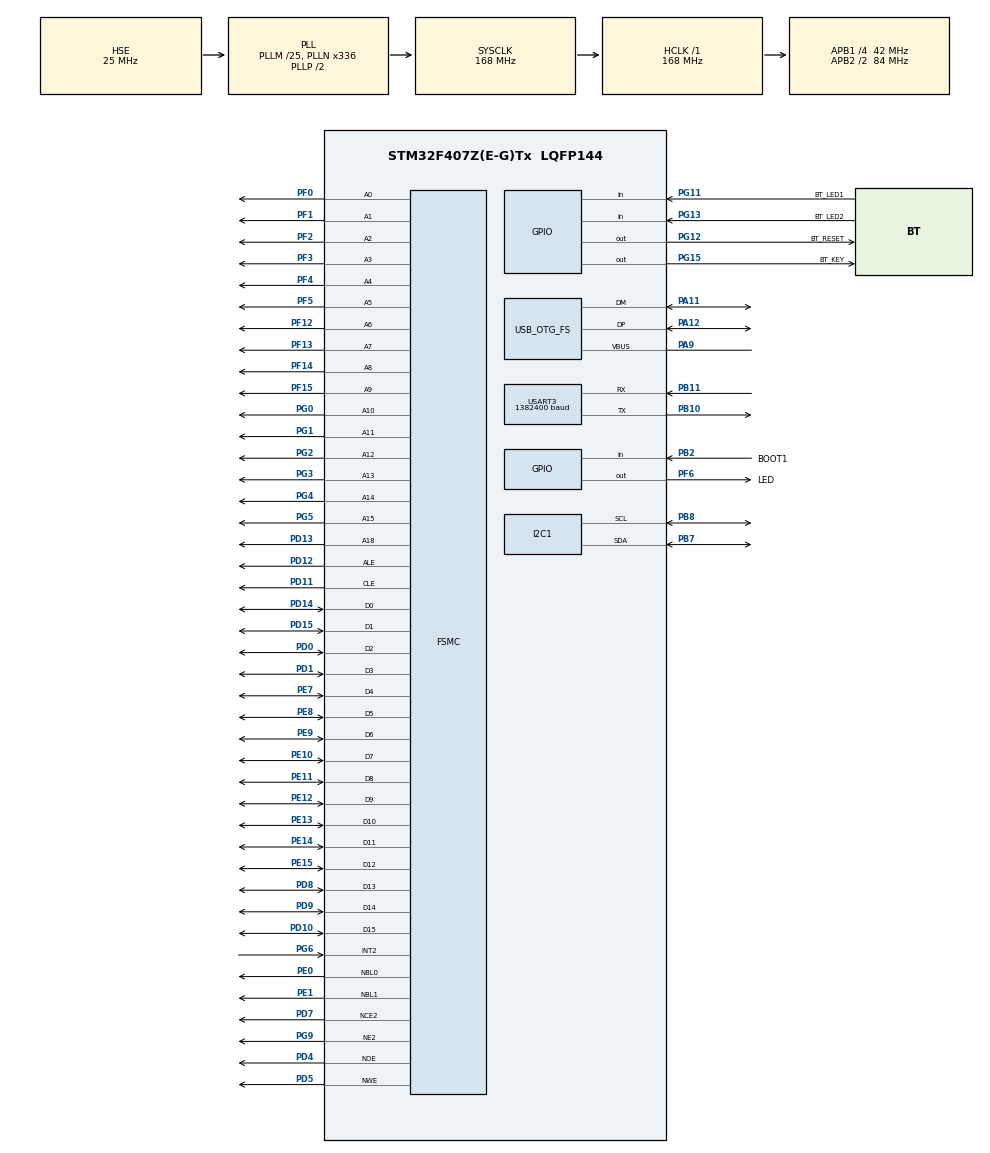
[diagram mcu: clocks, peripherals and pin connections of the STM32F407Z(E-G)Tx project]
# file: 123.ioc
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Dma.Request0=USART3_RX
Dma.Request1=USART3_TX
Dma.USART3_RX.0.Direction=DMA_PERIPH_TO_MEMORY
Dma.USART3_RX.0.FIFOMode=DMA_FIFOMODE_DISABLE
Dma.USART3_RX.0.Instance=DMA1_Stream1
Dma.USART3_RX.0.MemDataAlignment=DMA_MDATAALIGN_BYTE
Dma.USART3_RX.0.MemInc=DMA_MINC_ENABLE
Dma.USART3_RX.0.Mode=DMA_NORMAL
Dma.USART3_RX.0.PeriphDataAlignment=DMA_PDATAALIGN_BYTE
Dma.USART3_RX.0.PeriphInc=DMA_PINC_DISABLE
Dma.USART3_RX.0.Priority=DMA_PRIORITY_HIGH
Dma.USART3_TX.1.Direction=DMA_MEMORY_TO_PERIPH
Dma.USART3_TX.1.FIFOMode=DMA_FIFOMODE_DISABLE
Dma.USART3_TX.1.Instance=DMA1_Stream3
Dma.USART3_TX.1.MemDataAlignment=DMA_MDATAALIGN_BYTE
Dma.USART3_TX.1.MemInc=DMA_MINC_ENABLE
Dma.USART3_TX.1.Mode=DMA_NORMAL
Dma.USART3_TX.1.PeriphDataAlignment=DMA_PDATAALIGN_BYTE
Dma.USART3_TX.1.PeriphInc=DMA_PINC_DISABLE
Dma.USART3_TX.1.Priority=DMA_PRIORITY_LOW
FREERTOS.BinarySemaphores01=goToSendUSB,Dynamic,NULL
FREERTOS.HEAP_NUMBER=1
FREERTOS.INCLUDE_uxTaskPriorityGet=0
FREERTOS.INCLUDE_vTaskDelayUntil=0
FREERTOS.INCLUDE_vTaskDelete=0
FREERTOS.INCLUDE_vTaskPrioritySet=0
FREERTOS.Queues01=usbTransmitQueue,8,uint64_t,NULL,Dynamic,NULL,NULL
FREERTOS.Tasks01=defaultTask,-1,90,StartDefaultTask,As weak,NULL,Dynamic,NULL,NULL;usbTrans,-1,90,usbTransmit,As weak,NULL,Dynamic,NULL,NULL;myTask03,-1,90,taskIIC,As weak,NULL,Dynamic,NULL,NULL
FREERTOS.Timers01=statChange,statChangeTimer,osTimerPeriodic,As weak,NULL,Dynamic,NULL
FREERTOS.configMAX_TASK_NAME_LEN=12
FREERTOS.configMINIMAL_STACK_SIZE=90
FREERTOS.configTIMER_QUEUE_LENGTH=1
FREERTOS.configTIMER_TASK_PRIORITY=6
FREERTOS.configTIMER_TASK_STACK_DEPTH=90
FREERTOS.configTOTAL_HEAP_SIZE=3072
FREERTOS.configUSE_COUNTING_SEMAPHORES=0
FREERTOS.configUSE_TIMERS=1
Mcu.Family=STM32F4
Mcu.Name=STM32F407Z(E-G)Tx
Mcu.Package=LQFP144
NVIC.DMA1_Stream1_IRQn=true\:5\:0\:false\:false\:true\:true\:false
NVIC.DMA1_Stream3_IRQn=true\:5\:0\:true\:false\:true\:false\:false
NVIC.OTG_FS_IRQn=true\:5\:0\:true\:false\:true\:true\:true
NVIC.PriorityGroup=NVIC_PRIORITYGROUP_4
NVIC.TIM4_IRQn=true\:0\:0\:false\:false\:true\:false\:false
NVIC.TimeBase=TIM4_IRQn
NVIC.TimeBaseIP=TIM4
NVIC.USART3_IRQn=true\:5\:0\:true\:false\:true\:true\:true
PA11.Mode=Device_Only
PA11.Signal=USB_OTG_FS_DM
PA12.Mode=Device_Only
PA12.Signal=USB_OTG_FS_DP
PA13.Signal=SYS_JTMS-SWDIO
PA14.Signal=SYS_JTCK-SWCLK
PA9.Mode=Activate_VBUS
PA9.Signal=USB_OTG_FS_VBUS
PB10.Mode=Asynchronous
PB10.Signal=USART3_TX
PB11.Mode=Asynchronous
PB11.Signal=USART3_RX
PB2.GPIO_Label=BOOT1
PB2.Signal=GPIO_Input
PB3.Signal=SYS_JTDO-SWO
PB7.Mode=I2C
PB7.Signal=I2C1_SDA
PB8.Mode=I2C
PB8.Signal=I2C1_SCL
PC14-OSC32_IN.Mode=LSE-External-Oscillator
PC14-OSC32_IN.Signal=RCC_OSC32_IN
PC15-OSC32_OUT.Mode=LSE-External-Oscillator
PC15-OSC32_OUT.Signal=RCC_OSC32_OUT
PD0.Signal=FSMC_D2_DA2
PD1.Signal=FSMC_D3_DA3
PD10.Signal=FSMC_D15_DA15
PD11.Signal=FSMC_A16_CLE
PD12.Signal=FSMC_A17_ALE
PD13.Signal=FSMC_A18
PD14.Signal=FSMC_D0_DA0
PD15.Signal=FSMC_D1_DA1
PD4.Signal=FSMC_NOE
PD5.Signal=FSMC_NWE
PD7.Mode=NandChipSelect2_1
PD7.Signal=FSMC_NCE2
PD8.Signal=FSMC_D13_DA13
PD9.Signal=FSMC_D14_DA14
PE0.Signal=FSMC_NBL0
PE1.Signal=FSMC_NBL1
PE10.Signal=FSMC_D7_DA7
PE11.Signal=FSMC_D8_DA8
PE12.Signal=FSMC_D9_DA9
PE13.Signal=FSMC_D10_DA10
PE14.Signal=FSMC_D11_DA11
PE15.Signal=FSMC_D12_DA12
PE7.Signal=FSMC_D4_DA4
PE8.Signal=FSMC_D5_DA5
PE9.Signal=FSMC_D6_DA6
PF0.Signal=FSMC_A0
PF1.Signal=FSMC_A1
PF12.Signal=FSMC_A6
PF13.Signal=FSMC_A7
PF14.Signal=FSMC_A8
PF15.Signal=FSMC_A9
PF2.Signal=FSMC_A2
PF3.Signal=FSMC_A3
PF4.Signal=FSMC_A4
PF5.Signal=FSMC_A5
PF6.GPIO_Label=LED
PF6.Signal=GPIO_Output
PG0.Signal=FSMC_A10
PG1.Signal=FSMC_A11
PG11.GPIO_Label=BT_LED1
PG11.Signal=GPIO_Input
PG12.GPIO_Label=BT_RESET
PG12.GPIO_ModeDefaultOutputPP=GPIO_MODE_OUTPUT_OD
PG12.GPIO_PuPd=GPIO_NOPULL
PG12.PinState=GPIO_PIN_SET
PG12.Signal=GPIO_Output
PG13.GPIO_Label=BT_LED2
PG13.Signal=GPIO_Input
PG15.GPIO_Label=BT_KEY
PG15.GPIO_ModeDefaultOutputPP=GPIO_MODE_OUTPUT_PP
PG15.PinState=GPIO_PIN_RESET
PG15.Signal=GPIO_Output
PG2.Signal=FSMC_A12
PG3.Signal=FSMC_A13
PG4.Signal=FSMC_A14
PG5.Signal=FSMC_A15
PG6.Signal=FSMC_INT2
PG9.Mode=NorPsramChipSelect2_1
PG9.Signal=FSMC_NE2
PH0-OSC_IN.Mode=HSE-External-Oscillator
PH0-OSC_IN.Signal=RCC_OSC_IN
PH1-OSC_OUT.Mode=HSE-External-Oscillator
PH1-OSC_OUT.Signal=RCC_OSC_OUT
ProjectManager.HeapSize=0x600
ProjectManager.StackSize=0x800
ProjectManager.TargetToolchain=EWARM
RCC.48MHZClocksFreq_Value=48000000
RCC.AHBFreq_Value=168000000
RCC.APB1CLKDivider=RCC_HCLK_DIV4
RCC.APB1Freq_Value=42000000
RCC.APB1TimFreq_Value=84000000
RCC.APB2CLKDivider=RCC_HCLK_DIV2
RCC.APB2Freq_Value=84000000
RCC.APB2TimFreq_Value=168000000
RCC.CortexFreq_Value=168000000
RCC.EnbaleCSS=true
RCC.HCLKFreq_Value=168000000
RCC.HSE_VALUE=25000000
RCC.HSI_VALUE=16000000
RCC.PLLM=25
RCC.PLLN=336
RCC.PLLQ=7
RCC.RCC_RTC_Clock_SourceVirtual=RCC_RTCCLKSOURCE_LSE
RCC.SYSCLKFreq_VALUE=168000000
RCC.SYSCLKSource=RCC_SYSCLKSOURCE_PLLCLK
RCC.VCOOutputFreq_Value=336000000
SH.FSMC_A0.0=FSMC_A0,19b-a1
SH.FSMC_A1.0=FSMC_A1,19b-a1
SH.FSMC_A10.0=FSMC_A10,19b-a1
SH.FSMC_A11.0=FSMC_A11,19b-a1
SH.FSMC_A12.0=FSMC_A12,19b-a1
SH.FSMC_A13.0=FSMC_A13,19b-a1
SH.FSMC_A14.0=FSMC_A14,19b-a1
SH.FSMC_A15.0=FSMC_A15,19b-a1
SH.FSMC_A16_CLE.0=FSMC_CLE,8b-dmux1
SH.FSMC_A16_CLE.1=FSMC_A16,19b-a1
SH.FSMC_A17_ALE.0=FSMC_ALE,8b-dmux1
SH.FSMC_A17_ALE.1=FSMC_A17,19b-a1
SH.FSMC_A18.0=FSMC_A18,19b-a1
SH.FSMC_A2.0=FSMC_A2,19b-a1
SH.FSMC_A3.0=FSMC_A3,19b-a1
SH.FSMC_A4.0=FSMC_A4,19b-a1
SH.FSMC_A5.0=FSMC_A5,19b-a1
SH.FSMC_A6.0=FSMC_A6,19b-a1
SH.FSMC_A7.0=FSMC_A7,19b-a1
SH.FSMC_A8.0=FSMC_A8,19b-a1
SH.FSMC_A9.0=FSMC_A9,19b-a1
SH.FSMC_D0_DA0.0=FSMC_D0,8b-dmux1
SH.FSMC_D0_DA0.1=FSMC_D0,16b-d1
SH.FSMC_D10_DA10.0=FSMC_D10,16b-d1
SH.FSMC_D11_DA11.0=FSMC_D11,16b-d1
SH.FSMC_D12_DA12.0=FSMC_D12,16b-d1
SH.FSMC_D13_DA13.0=FSMC_D13,16b-d1
SH.FSMC_D14_DA14.0=FSMC_D14,16b-d1
SH.FSMC_D15_DA15.0=FSMC_D15,16b-d1
SH.FSMC_D1_DA1.0=FSMC_D1,8b-dmux1
SH.FSMC_D1_DA1.1=FSMC_D1,16b-d1
SH.FSMC_D2_DA2.0=FSMC_D2,8b-dmux1
SH.FSMC_D2_DA2.1=FSMC_D2,16b-d1
SH.FSMC_D3_DA3.0=FSMC_D3,8b-dmux1
SH.FSMC_D3_DA3.1=FSMC_D3,16b-d1
SH.FSMC_D4_DA4.0=FSMC_D4,8b-dmux1
SH.FSMC_D4_DA4.1=FSMC_D4,16b-d1
SH.FSMC_D5_DA5.0=FSMC_D5,8b-dmux1
SH.FSMC_D5_DA5.1=FSMC_D5,16b-d1
SH.FSMC_D6_DA6.0=FSMC_D6,8b-dmux1
SH.FSMC_D6_DA6.1=FSMC_D6,16b-d1
SH.FSMC_D7_DA7.0=FSMC_D7,8b-dmux1
SH.FSMC_D7_DA7.1=FSMC_D7,16b-d1
SH.FSMC_D8_DA8.0=FSMC_D8,16b-d1
SH.FSMC_D9_DA9.0=FSMC_D9,16b-d1
SH.FSMC_INT2.0=FSMC_INT2,Interrupt21
SH.FSMC_NBL0.0=FSMC_NBL0,2ByteEnable1
SH.FSMC_NBL1.0=FSMC_NBL1,2ByteEnable1
SH.FSMC_NOE.0=FSMC_NOE,8b-dmux1
SH.FSMC_NOE.1=FSMC_NOE,Sram1
SH.FSMC_NWE.0=FSMC_NWE,8b-dmux1
SH.FSMC_NWE.1=FSMC_NWE,Sram1
USART3.BaudRate=1382400
USART3.Mode=MODE_TX_RX
USART3.OverSampling=UART_OVERSAMPLING_16
USART3.VirtualMode=VM_ASYNC
USB_OTG_FS.VirtualMode=Device_Only
VP_FREERTOS_VS_ENABLE.Mode=Enabled
VP_SYS_VS_tim4.Mode=TIM4
board=123

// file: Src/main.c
/**
  ******************************************************************************
  * File Name          : main.c
  * Description        : Main program body
  ******************************************************************************
  * This notice applies to any and all portions of this file
  * that are not between comment pairs USER CODE BEGIN and
  * USER CODE END. Other portions of this file, whether
  * inserted by the user or by software development tools
  * are owned by their respective copyright owners.
  *
  * Copyright (c) 2017 STMicroelectronics International N.V.
  * All rights reserved.
  *
  * Redistribution and use in source and binary forms, with or without
  * modification, are permitted, provided that the following conditions are met:
  *
  * 1. Redistribution of source code must retain the above copyright notice,
  *    this list of conditions and the following disclaimer.
  * 2. Redistributions in binary form must reproduce the above copyright notice,
  *    this list of conditions and the following disclaimer in the documentation
  *    and/or other materials provided with the distribution.
  * 3. Neither the name of STMicroelectronics nor the names of other
  *    contributors to this software may be used to endorse or promote products
  *    derived from this software without specific written permission.
  * 4. This software, including modifications and/or derivative works of this
  *    software, must execute solely and exclusively on microcontroller or
  *    microprocessor devices manufactured by or for STMicroelectronics.
  * 5. Redistribution and use of this software other than as permitted under
  *    this license is void and will automatically terminate your rights under
  *    this license.
  *
  * THIS SOFTWARE IS PROVIDED BY STMICROELECTRONICS AND CONTRIBUTORS "AS IS"
  * AND ANY EXPRESS, IMPLIED OR STATUTORY WARRANTIES, INCLUDING, BUT NOT
  * LIMITED TO, THE IMPLIED WARRANTIES OF MERCHANTABILITY, FITNESS FOR A
  * PARTICULAR PURPOSE AND NON-INFRINGEMENT OF THIRD PARTY INTELLECTUAL PROPERTY
  * RIGHTS ARE DISCLAIMED TO THE FULLEST EXTENT PERMITTED BY LAW. IN NO EVENT
  * SHALL STMICROELECTRONICS OR CONTRIBUTORS BE LIABLE FOR ANY DIRECT, INDIRECT,
  * INCIDENTAL, SPECIAL, EXEMPLARY, OR CONSEQUENTIAL DAMAGES (INCLUDING, BUT NOT
  * LIMITED TO, PROCUREMENT OF SUBSTITUTE GOODS OR SERVICES; LOSS OF USE, DATA,
  * OR PROFITS; OR BUSINESS INTERRUPTION) HOWEVER CAUSED AND ON ANY THEORY OF
  * LIABILITY, WHETHER IN CONTRACT, STRICT LIABILITY, OR TORT (INCLUDING
  * NEGLIGENCE OR OTHERWISE) ARISING IN ANY WAY OUT OF THE USE OF THIS SOFTWARE,
  * EVEN IF ADVISED OF THE POSSIBILITY OF SUCH DAMAGE.
  *
  ******************************************************************************
  */

#include "main.h"
#include "stm32f4xx_hal.h"
#include "cmsis_os.h"
#include "dma.h"
#include "i2c.h"
#include "usart.h"
#include "usb_otg.h"
#include "gpio.h"
#include "fsmc.h"

/* USER CODE BEGIN PV */
/* Private variables ---------------------------------------------------------*/

/* USER CODE END PV */

void SystemClock_Config(void);
void MX_FREERTOS_Init(void);

/* USER CODE BEGIN PFP */
/* Private function prototypes -----------------------------------------------*/

/* USER CODE END PFP */

int main(void)
{

  /* MCU Configuration----------------------------------------------------------*/

  /* Reset of all peripherals, Initializes the Flash interface and the Systick. */
  HAL_Init();

  /* Configure the system clock */
  SystemClock_Config();

  /* USER CODE BEGIN SysInit */
#ifdef _KJKJKJKJ
  /* USER CODE END SysInit */

  /* Initialize all configured peripherals */
  MX_GPIO_Init();
  MX_DMA_Init();
  MX_FSMC_Init();
  MX_USART3_UART_Init();
  MX_USB_OTG_FS_PCD_Init();
  MX_I2C1_Init();

  /* USER CODE BEGIN 2 */
#endif

  MX_GPIO_Init();
  MX_DMA_Init();
  MX_FSMC_Init();
  MX_USART3_UART_Init();
  MX_USB_OTG_FS_PCD_Init();
  MX_I2C1_Init();

  /* USER CODE END 2 */

  /* Call init function for freertos objects (in freertos.c) */
  MX_FREERTOS_Init();

  /* Start scheduler */
  osKernelStart();

  /* We should never get here as control is now taken by the scheduler */

  /* Infinite loop */
  while (1)
  {

  }

}

/** System Clock Configuration
*/
void SystemClock_Config(void)
{

  RCC_OscInitTypeDef RCC_OscInitStruct;
  RCC_ClkInitTypeDef RCC_ClkInitStruct;

    /**Configure the main internal regulator output voltage
    */
  __HAL_RCC_PWR_CLK_ENABLE();

  __HAL_PWR_VOLTAGESCALING_CONFIG(PWR_REGULATOR_VOLTAGE_SCALE1);

    /**Initializes the CPU, AHB and APB busses clocks
    */
  RCC_OscInitStruct.OscillatorType = RCC_OSCILLATORTYPE_HSE;
  RCC_OscInitStruct.HSEState = RCC_HSE_ON;
  RCC_OscInitStruct.PLL.PLLState = RCC_PLL_ON;
  RCC_OscInitStruct.PLL.PLLSource = RCC_PLLSOURCE_HSE;
  RCC_OscInitStruct.PLL.PLLM = 25;
  RCC_OscInitStruct.PLL.PLLN = 336;
  RCC_OscInitStruct.PLL.PLLP = RCC_PLLP_DIV2;
  RCC_OscInitStruct.PLL.PLLQ = 7;
  if (HAL_RCC_OscConfig(&RCC_OscInitStruct) != HAL_OK)
  {
    _Error_Handler(__FILE__, __LINE__);
  }

    /**Initializes the CPU, AHB and APB busses clocks
    */
  RCC_ClkInitStruct.ClockType = RCC_CLOCKTYPE_HCLK|RCC_CLOCKTYPE_SYSCLK
                              |RCC_CLOCKTYPE_PCLK1|RCC_CLOCKTYPE_PCLK2;
  RCC_ClkInitStruct.SYSCLKSource = RCC_SYSCLKSOURCE_PLLCLK;
  RCC_ClkInitStruct.AHBCLKDivider = RCC_SYSCLK_DIV1;
  RCC_ClkInitStruct.APB1CLKDivider = RCC_HCLK_DIV4;
  RCC_ClkInitStruct.APB2CLKDivider = RCC_HCLK_DIV2;

  if (HAL_RCC_ClockConfig(&RCC_ClkInitStruct, FLASH_LATENCY_5) != HAL_OK)
  {
    _Error_Handler(__FILE__, __LINE__);
  }

    /**Enables the Clock Security System
    */
  HAL_RCC_EnableCSS();

    /**Configure the Systick interrupt time
    */
  HAL_SYSTICK_Config(HAL_RCC_GetHCLKFreq()/1000);

    /**Configure the Systick
    */
  HAL_SYSTICK_CLKSourceConfig(SYSTICK_CLKSOURCE_HCLK);

  /* SysTick_IRQn interrupt configuration */
  HAL_NVIC_SetPriority(SysTick_IRQn, 15, 0);
}

void HAL_TIM_PeriodElapsedCallback(TIM_HandleTypeDef *htim)
{
  if (htim->Instance == TIM4) {
    HAL_IncTick();
  }
}

void _Error_Handler(char * file, int line)
{
  /* USER CODE BEGIN Error_Handler_Debug */
  /* User can add his own implementation to report the HAL error return state */
  while(1)
  {
      HAL_GPIO_TogglePin(LED_GPIO_Port,LED_Pin);
      HAL_Delay(300);
  }
  /* USER CODE END Error_Handler_Debug */
}

/************************ (C) COPYRIGHT STMicroelectronics *****END OF FILE****/

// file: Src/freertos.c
/**
  ******************************************************************************
  * File Name          : freertos.c
  * Description        : Code for freertos applications
  ******************************************************************************
  * This notice applies to any and all portions of this file
  * that are not between comment pairs USER CODE BEGIN and
  * USER CODE END. Other portions of this file, whether
  * inserted by the user or by software development tools
  * are owned by their respective copyright owners.
  *
  * Copyright (c) 2017 STMicroelectronics International N.V.
  * All rights reserved.
  *
  * Redistribution and use in source and binary forms, with or without
  * modification, are permitted, provided that the following conditions are met:
  *
  * 1. Redistribution of source code must retain the above copyright notice,
  *    this list of conditions and the following disclaimer.
  * 2. Redistributions in binary form must reproduce the above copyright notice,
  *    this list of conditions and the following disclaimer in the documentation
  *    and/or other materials provided with the distribution.
  * 3. Neither the name of STMicroelectronics nor the names of other
  *    contributors to this software may be used to endorse or promote products
  *    derived from this software without specific written permission.
  * 4. This software, including modifications and/or derivative works of this
  *    software, must execute solely and exclusively on microcontroller or
  *    microprocessor devices manufactured by or for STMicroelectronics.
  * 5. Redistribution and use of this software other than as permitted under
  *    this license is void and will automatically terminate your rights under
  *    this license.
  *
  * THIS SOFTWARE IS PROVIDED BY STMICROELECTRONICS AND CONTRIBUTORS "AS IS"
  * AND ANY EXPRESS, IMPLIED OR STATUTORY WARRANTIES, INCLUDING, BUT NOT
  * LIMITED TO, THE IMPLIED WARRANTIES OF MERCHANTABILITY, FITNESS FOR A
  * PARTICULAR PURPOSE AND NON-INFRINGEMENT OF THIRD PARTY INTELLECTUAL PROPERTY
  * RIGHTS ARE DISCLAIMED TO THE FULLEST EXTENT PERMITTED BY LAW. IN NO EVENT
  * SHALL STMICROELECTRONICS OR CONTRIBUTORS BE LIABLE FOR ANY DIRECT, INDIRECT,
  * INCIDENTAL, SPECIAL, EXEMPLARY, OR CONSEQUENTIAL DAMAGES (INCLUDING, BUT NOT
  * LIMITED TO, PROCUREMENT OF SUBSTITUTE GOODS OR SERVICES; LOSS OF USE, DATA,
  * OR PROFITS; OR BUSINESS INTERRUPTION) HOWEVER CAUSED AND ON ANY THEORY OF
  * LIABILITY, WHETHER IN CONTRACT, STRICT LIABILITY, OR TORT (INCLUDING
  * NEGLIGENCE OR OTHERWISE) ARISING IN ANY WAY OUT OF THE USE OF THIS SOFTWARE,
  * EVEN IF ADVISED OF THE POSSIBILITY OF SUCH DAMAGE.
  *
  ******************************************************************************
  */

#include "FreeRTOS.h"
#include "task.h"
#include "cmsis_os.h"

osThreadId defaultTaskHandle;
osThreadId usbTransHandle;
osThreadId myTask03Handle;
osMessageQId usbTransmitQueueHandle;
osTimerId statChangeHandle;
osSemaphoreId goToSendUSBHandle;

void StartDefaultTask(void const * argument);
void usbTransmit(void const * argument);
void taskIIC(void const * argument);
void statChangeTimer(void const * argument);

void MX_FREERTOS_Init(void); /* (MISRA C 2004 rule 8.1) */

/* Hook prototypes */

/* Init FreeRTOS */

void MX_FREERTOS_Init(void) {

  /* Create the semaphores(s) */
  /* definition and creation of goToSendUSB */
  osSemaphoreDef(goToSendUSB);
  goToSendUSBHandle = osSemaphoreCreate(osSemaphore(goToSendUSB), 1);

  /* Create the timer(s) */
  /* definition and creation of statChange */
  osTimerDef(statChange, statChangeTimer);
  statChangeHandle = osTimerCreate(osTimer(statChange), osTimerPeriodic, NULL);

  /* Create the thread(s) */
  /* definition and creation of defaultTask */
  osThreadDef(defaultTask, StartDefaultTask, osPriorityBelowNormal, 0, 90);
  defaultTaskHandle = osThreadCreate(osThread(defaultTask), NULL);

  /* definition and creation of usbTrans */
  osThreadDef(usbTrans, usbTransmit, osPriorityBelowNormal, 0, 90);
  usbTransHandle = osThreadCreate(osThread(usbTrans), NULL);

  /* definition and creation of myTask03 */
  osThreadDef(myTask03, taskIIC, osPriorityBelowNormal, 0, 90);
  myTask03Handle = osThreadCreate(osThread(myTask03), NULL);

  /* Create the queue(s) */
  /* definition and creation of usbTransmitQueue */
  osMessageQDef(usbTransmitQueue, 8, uint64_t);
  usbTransmitQueueHandle = osMessageCreate(osMessageQ(usbTransmitQueue), NULL);

}

/* StartDefaultTask function */
__weak void StartDefaultTask(void const * argument)
{

  for(;;)
  {
    osDelay(1);
  }
}

/* usbTransmit function */
__weak void usbTransmit(void const * argument)
{
  for(;;)
  {
    osDelay(1);
  }
}

/* taskIIC function */
__weak void taskIIC(void const * argument)
{
  for(;;)
  {
    osDelay(1);
  }
}

/* statChangeTimer function */
__weak void statChangeTimer(void const * argument)
{
}

/************************ (C) COPYRIGHT STMicroelectronics *****END OF FILE****/
